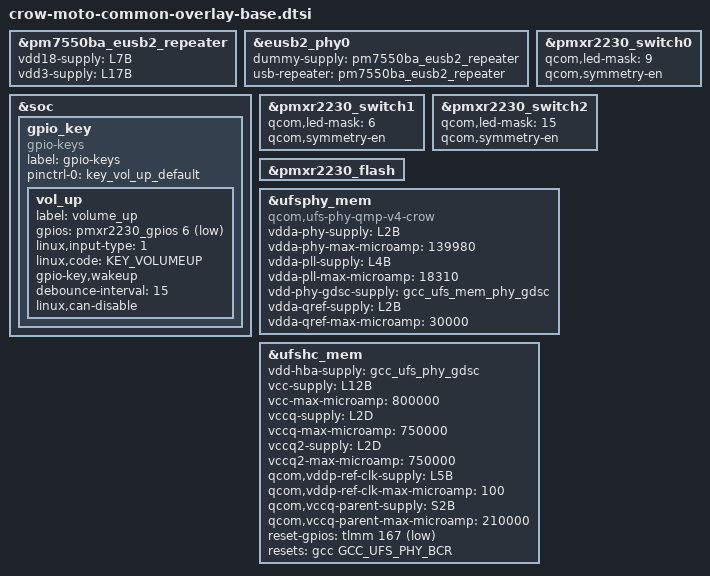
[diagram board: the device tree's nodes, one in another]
/* Copyright (c) 2023, The Linux Foundation. All rights reserved.
 *
 * This program is free software; you can redistribute it and/or modify
 * it under the terms of the GNU General Public License version 2 and
 * only version 2 as published by the Free Software Foundation.
 *
 * This program is distributed in the hope that it will be useful,
 * but WITHOUT ANY WARRANTY; without even the implied warranty of
 * MERCHANTABILITY or FITNESS FOR A PARTICULAR PURPOSE.  See the
 * GNU General Public License for more details.
 */

/*
   This base is original from "crow-dp.dtsi"
*/
#include <dt-bindings/clock/qcom,gcc-crow.h>
#include <dt-bindings/gpio/gpio.h>
#include "crow-pmic-overlay.dtsi"
#include "crow-thermal-overlay.dtsi"
#include "crow-pm7550ba.dtsi"

&pm7550ba_eusb2_repeater {
	vdd18-supply = <&L7B>;
	vdd3-supply = <&L17B>;
	status = "ok";
};

&eusb2_phy0 {
	dummy-supply = <&pm7550ba_eusb2_repeater>;
	usb-repeater = <&pm7550ba_eusb2_repeater>;
};

&soc {
	gpio_key {
		compatible = "gpio-keys";
		label = "gpio-keys";
		pinctrl-names = "default";
		pinctrl-0 = <&key_vol_up_default>;
		vol_up {
			label = "volume_up";
			gpios = <&pmxr2230_gpios 6 GPIO_ACTIVE_LOW>;
			linux,input-type = <1>;
			linux,code = <KEY_VOLUMEUP>;
			gpio-key,wakeup;
			debounce-interval = <15>;
			linux,can-disable;
		};
	};
};

&pmxr2230_switch0 {
	qcom,led-mask = <9>; /* Channels 1 & 4 */
	qcom,symmetry-en;
};

&pmxr2230_switch1 {
	qcom,led-mask = <6>; /* Channels 2 & 3 */
	qcom,symmetry-en;
};

&pmxr2230_switch2 {
	qcom,led-mask = <15>; /* All Channels */
	qcom,symmetry-en;
};

&pmxr2230_flash {
	status = "ok";
};

&ufsphy_mem {
	compatible = "qcom,ufs-phy-qmp-v4-crow";

	/* VDDA_UFS_CORE */
	vdda-phy-supply = <&L2B>;
	vdda-phy-max-microamp = <139980>;

	/* VDDA_UFS_0_1P2 */
	vdda-pll-supply = <&L4B>;
	vdda-pll-max-microamp = <18310>;

	/* Phy GDSC for VDD_MX, always on */
	vdd-phy-gdsc-supply = <&gcc_ufs_mem_phy_gdsc>;

	/* Qref power supply, Refer Qref diagram */
	vdda-qref-supply = <&L2B>;
	vdda-qref-max-microamp = <30000>;

	status = "ok";
};

&ufshc_mem {
	vdd-hba-supply = <&gcc_ufs_phy_gdsc>;

	vcc-supply = <&L12B>;
	vcc-max-microamp = <800000>;

	vccq-supply = <&L2D>;
	vccq-max-microamp = <750000>;

	vccq2-supply = <&L2D>;
	vccq2-max-microamp = <750000>;

	/* VDD_PX10 is voted for the ufs_reset_n */
	qcom,vddp-ref-clk-supply = <&L5B>;
	qcom,vddp-ref-clk-max-microamp = <100>;

	qcom,vccq-parent-supply = <&S2B>;
	qcom,vccq-parent-max-microamp = <210000>;

	reset-gpios = <&tlmm 167 GPIO_ACTIVE_LOW>;
	resets = <&gcc GCC_UFS_PHY_BCR>;
	reset-names = "rst";

	status = "ok";
};
